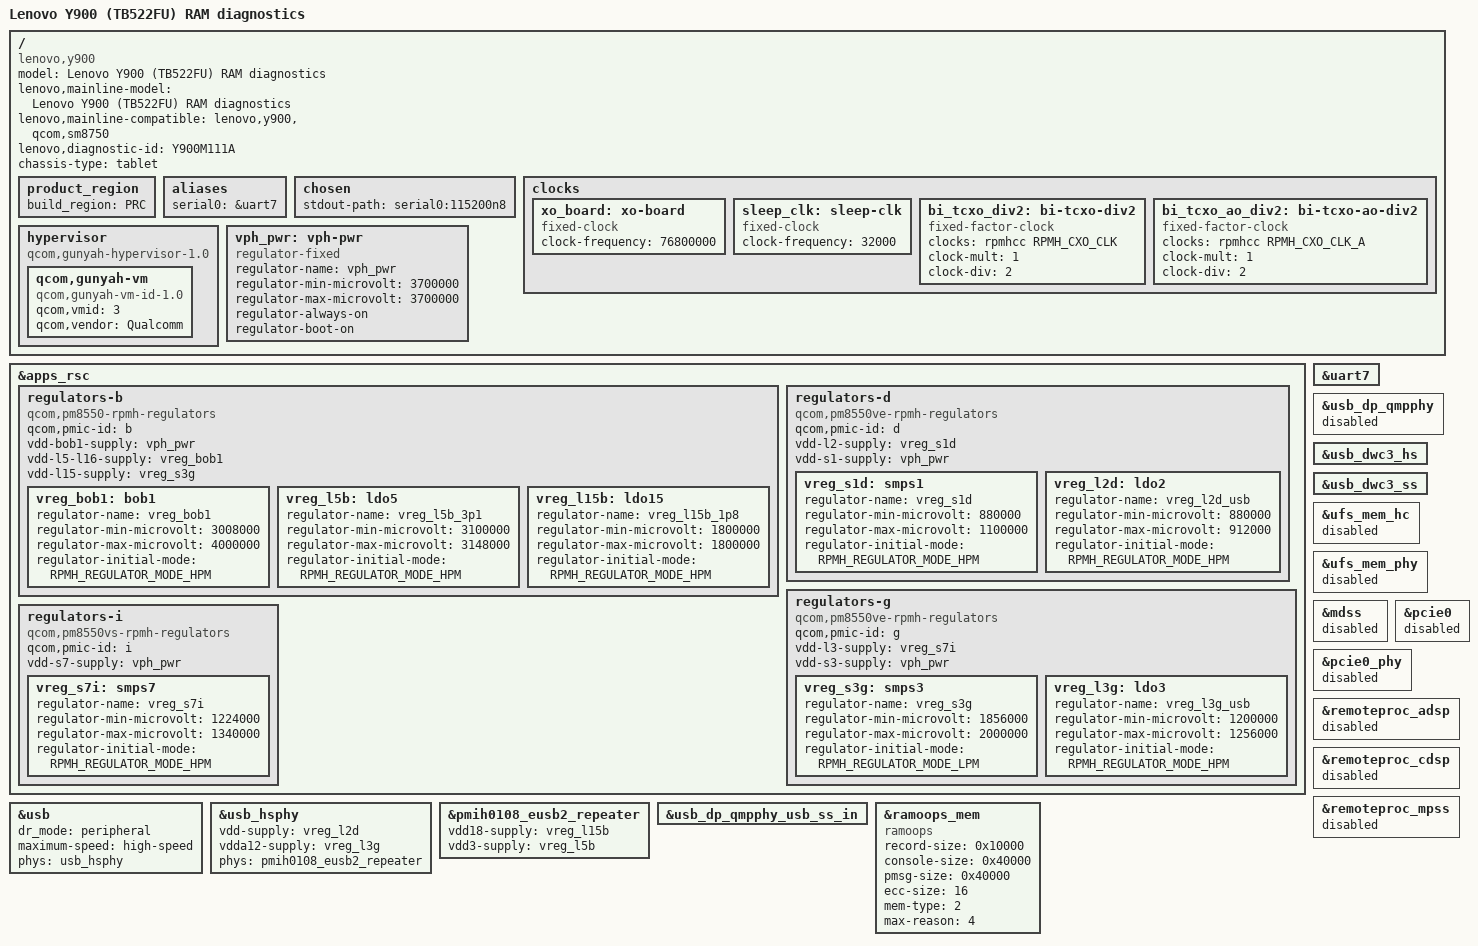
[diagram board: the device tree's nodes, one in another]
// SPDX-License-Identifier: BSD-3-Clause
// USB2-only RAM diagnosis. Board supply values come from this Y900's stock FDT.
/dts-v1/;
#include <dt-bindings/regulator/qcom,rpmh-regulator.h>
#include "sm8750.dtsi"
#include "pm8550.dtsi"
#include "pmih0108.dtsi"
#include "pmk8550.dtsi"
#include "sm8750-pmics.dtsi"

/ {
 model = "Lenovo Y900 (TB522FU) RAM diagnostics";
 compatible = "lenovo,y900", "qcom,sm8750";
 lenovo,mainline-model = "Lenovo Y900 (TB522FU) RAM diagnostics";
 lenovo,mainline-compatible = "lenovo,y900", "qcom,sm8750";
 lenovo,diagnostic-id = "Y900M111A";
 chassis-type = "tablet";
 product_region { build_region = "PRC"; };
 aliases { serial0 = &uart7; };
 chosen { stdout-path = "serial0:115200n8"; };
 clocks {
  xo_board: xo-board { compatible = "fixed-clock"; clock-frequency = <76800000>; #clock-cells = <0>; };
  sleep_clk: sleep-clk { compatible = "fixed-clock"; clock-frequency = <32000>; #clock-cells = <0>; };
  bi_tcxo_div2: bi-tcxo-div2 { compatible = "fixed-factor-clock"; #clock-cells = <0>; clocks = <&rpmhcc RPMH_CXO_CLK>; clock-mult = <1>; clock-div = <2>; };
  bi_tcxo_ao_div2: bi-tcxo-ao-div2 { compatible = "fixed-factor-clock"; #clock-cells = <0>; clocks = <&rpmhcc RPMH_CXO_CLK_A>; clock-mult = <1>; clock-div = <2>; };
 };
 hypervisor {
  compatible = "qcom,gunyah-hypervisor-1.0", "qcom,gunyah-hypervisor", "simple-bus";
  #address-cells = <2>; #size-cells = <0>;
  qcom,gunyah-vm { compatible = "qcom,gunyah-vm-id-1.0", "qcom,gunyah-vm-id"; qcom,vmid = <3>; qcom,vendor = "Qualcomm"; };
 };
 vph_pwr: vph-pwr {
  compatible = "regulator-fixed"; regulator-name = "vph_pwr";
  regulator-min-microvolt = <3700000>; regulator-max-microvolt = <3700000>;
  regulator-always-on; regulator-boot-on;
 };
};

&apps_rsc {
 regulators-b {
  compatible = "qcom,pm8550-rpmh-regulators"; qcom,pmic-id = "b";
  vdd-bob1-supply = <&vph_pwr>;
  vdd-l5-l16-supply = <&vreg_bob1>;
  vdd-l15-supply = <&vreg_s3g>;
  vreg_bob1: bob1 { regulator-name = "vreg_bob1"; regulator-min-microvolt = <3008000>; regulator-max-microvolt = <4000000>; regulator-initial-mode = <RPMH_REGULATOR_MODE_HPM>; };
  vreg_l5b: ldo5 { regulator-name = "vreg_l5b_3p1"; regulator-min-microvolt = <3100000>; regulator-max-microvolt = <3148000>; regulator-initial-mode = <RPMH_REGULATOR_MODE_HPM>; };
  vreg_l15b: ldo15 { regulator-name = "vreg_l15b_1p8"; regulator-min-microvolt = <1800000>; regulator-max-microvolt = <1800000>; regulator-initial-mode = <RPMH_REGULATOR_MODE_HPM>; };
 };
 regulators-d {
  compatible = "qcom,pm8550ve-rpmh-regulators"; qcom,pmic-id = "d";
  vdd-l2-supply = <&vreg_s1d>; vdd-s1-supply = <&vph_pwr>;
  vreg_s1d: smps1 { regulator-name = "vreg_s1d"; regulator-min-microvolt = <880000>; regulator-max-microvolt = <1100000>; regulator-initial-mode = <RPMH_REGULATOR_MODE_HPM>; };
  vreg_l2d: ldo2 { regulator-name = "vreg_l2d_usb"; regulator-min-microvolt = <880000>; regulator-max-microvolt = <912000>; regulator-initial-mode = <RPMH_REGULATOR_MODE_HPM>; };
 };
 regulators-g {
  compatible = "qcom,pm8550ve-rpmh-regulators"; qcom,pmic-id = "g";
  vdd-l3-supply = <&vreg_s7i>; vdd-s3-supply = <&vph_pwr>;
  vreg_s3g: smps3 { regulator-name = "vreg_s3g"; regulator-min-microvolt = <1856000>; regulator-max-microvolt = <2000000>; regulator-initial-mode = <RPMH_REGULATOR_MODE_LPM>; };
  vreg_l3g: ldo3 { regulator-name = "vreg_l3g_usb"; regulator-min-microvolt = <1200000>; regulator-max-microvolt = <1256000>; regulator-initial-mode = <RPMH_REGULATOR_MODE_HPM>; };
 };
 regulators-i {
  compatible = "qcom,pm8550vs-rpmh-regulators"; qcom,pmic-id = "i";
  vdd-s7-supply = <&vph_pwr>;
  vreg_s7i: smps7 { regulator-name = "vreg_s7i"; regulator-min-microvolt = <1224000>; regulator-max-microvolt = <1340000>; regulator-initial-mode = <RPMH_REGULATOR_MODE_HPM>; };
 };
};
&uart7 { status = "okay"; };
&usb {
 status = "okay";
 dr_mode = "peripheral";
 maximum-speed = "high-speed";
 phys = <&usb_hsphy>;
 phy-names = "usb2-phy";
 /delete-property/ usb-role-switch;
};
&usb_hsphy {
 vdd-supply = <&vreg_l2d>; vdda12-supply = <&vreg_l3g>;
 phys = <&pmih0108_eusb2_repeater>;
 status = "okay";
};
&pmih0108_eusb2_repeater {
 vdd18-supply = <&vreg_l15b>; vdd3-supply = <&vreg_l5b>;
 status = "okay";
};
&usb_dp_qmpphy { status = "disabled"; };
&usb_dwc3_hs { /delete-property/ remote-endpoint; };
&usb_dwc3_ss { /delete-property/ remote-endpoint; };
&usb_dp_qmpphy_usb_ss_in { /delete-property/ remote-endpoint; };
&ufs_mem_hc { status = "disabled"; };
&ufs_mem_phy { status = "disabled"; };
&mdss { status = "disabled"; };
&pcie0 { status = "disabled"; };
&pcie0_phy { status = "disabled"; };
&remoteproc_adsp { status = "disabled"; };
&remoteproc_cdsp { status = "disabled"; };
&remoteproc_mpss { status = "disabled"; };

&ramoops_mem {
 compatible = "ramoops";
 record-size = <0x10000>; console-size = <0x40000>; pmsg-size = <0x40000>;
 ecc-size = <16>; mem-type = <2>; max-reason = <4>;
};
